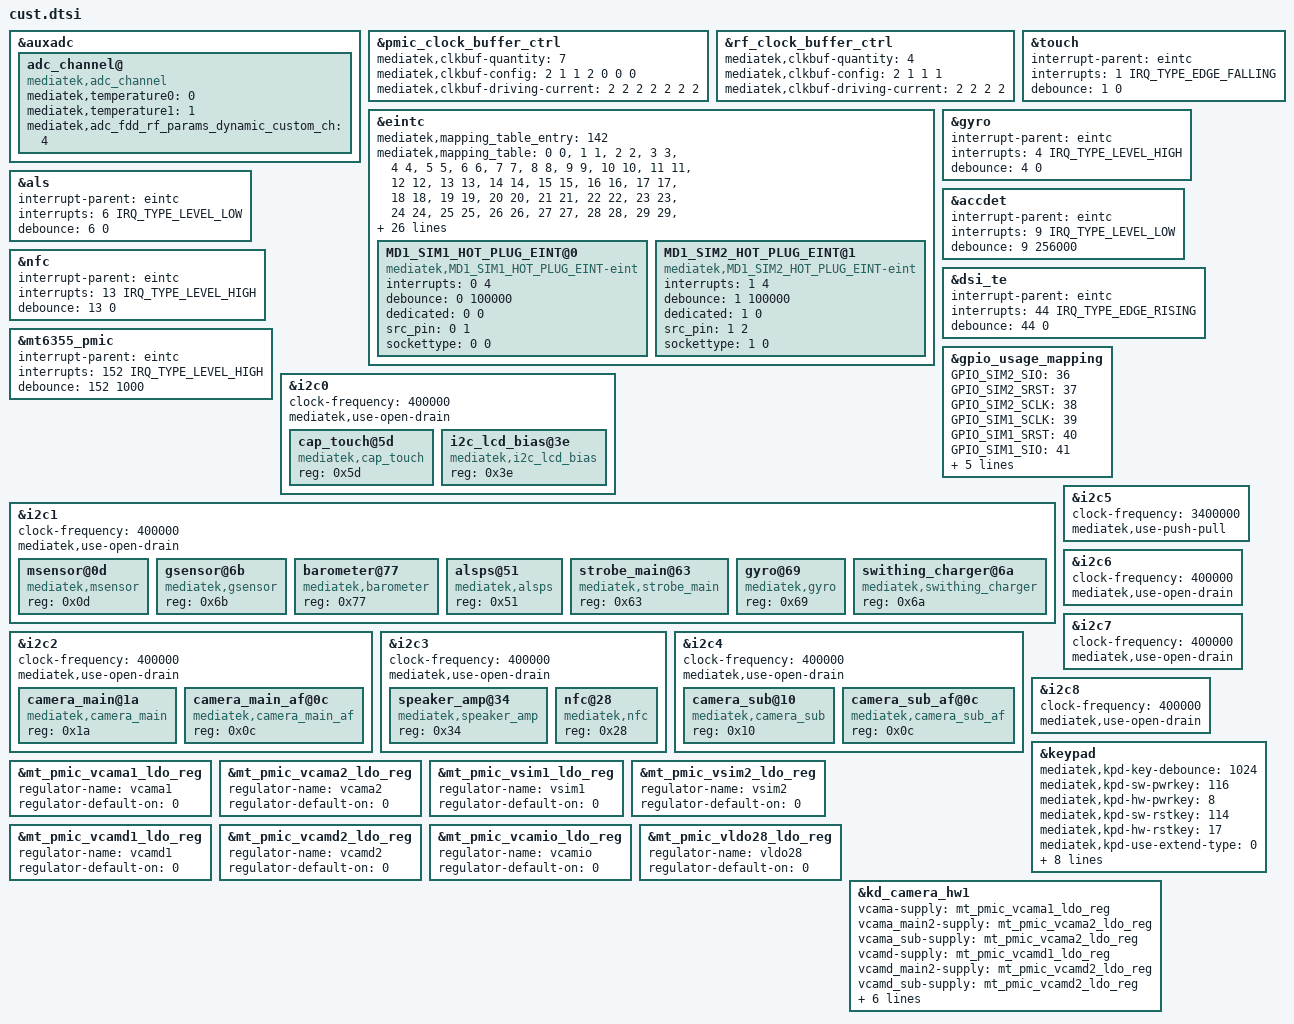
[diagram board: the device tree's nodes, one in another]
/*
 * Generated by MTK SP DrvGen Version: 3.5.160809 for MT6757-P25.
 * 2016-12-20 20:41:03
 * Do Not Modify The File.
 * Copyright Mediatek Inc. (c) 2016.
*/

/*************************
 * ADC DTSI File
*************************/

&auxadc {
	adc_channel@ {
		compatible = "mediatek,adc_channel";
		mediatek,temperature0 = <0>;
		mediatek,temperature1 = <1>;
		mediatek,adc_fdd_rf_params_dynamic_custom_ch = <4>;
		status = "okay";
	};
};


/*************************
 * CLK_BUF DTSI File
*************************/

&pmic_clock_buffer_ctrl {
	mediatek,clkbuf-quantity = <7>;
	mediatek,clkbuf-config = <2 1 1 2 0 0 0>;
	mediatek,clkbuf-driving-current = <2 2 2 2 2 2 2>;
	status = "okay";
};

&rf_clock_buffer_ctrl {
	mediatek,clkbuf-quantity = <4>;
	mediatek,clkbuf-config = <2 1 1 1>;
	mediatek,clkbuf-driving-current = <2 2 2 2 >;
	status = "okay";
};


/*************************
 * EINT DTSI File
*************************/

#include <dt-bindings/interrupt-controller/irq.h>
#include <dt-bindings/interrupt-controller/arm-gic.h>

&eintc {
	mediatek,mapping_table_entry = <142>;
			/* <gpio_pin, eint_pin> */
	mediatek,mapping_table = <0 0>,
					<1 1>,
					<2 2>,
					<3 3>,
					<4 4>,
					<5 5>,
					<6 6>,
					<7 7>,
					<8 8>,
					<9 9>,
					<10 10>,
					<11 11>,
					<12 12>,
					<13 13>,
					<14 14>,
					<15 15>,
					<16 16>,
					<17 17>,
					<18 18>,
					<19 19>,
					<20 20>,
					<21 21>,
					<22 22>,
					<23 23>,
					<24 24>,
					<25 25>,
					<26 26>,
					<27 27>,
					<28 28>,
					<29 29>,
					<30 30>,
					<31 31>,
					<32 32>,
					<33 33>,
					<34 34>,
					<35 35>,
					<36 36>,
					<37 37>,
					<38 38>,
					<39 39>,
					<40 40>,
					<41 41>,
					<42 42>,
					<43 43>,
					<44 44>,
					<45 45>,
					<46 46>,
					<47 47>,
					<48 48>,
					<49 49>,
					<50 50>,
					<51 51>,
					<52 52>,
					<53 53>,
					<54 54>,
					<55 55>,
					<56 56>,
					<57 57>,
					<58 58>,
					<59 59>,
					<60 60>,
					<61 61>,
					<62 62>,
					<63 63>,
					<64 64>,
					<65 65>,
					<66 66>,
					<67 67>,
					<68 68>,
					<69 69>,
					<75 75>,
					<76 76>,
					<77 77>,
					<78 78>,
					<79 79>,
					<80 80>,
					<81 81>,
					<82 82>,
					<83 83>,
					<84 84>,
					<85 85>,
					<86 86>,
					<87 87>,
					<88 88>,
					<89 89>,
					<90 90>,
					<91 91>,
					<92 92>,
					<93 93>,
					<94 94>,
					<95 95>,
					<96 96>,
					<97 97>,
					<98 98>,
					<99 99>,
					<100 100>,
					<101 101>,
					<102 102>,
					<103 103>,
					<104 104>,
					<105 105>,
					<106 106>,
					<107 107>,
					<108 108>,
					<109 109>,
					<110 110>,
					<111 111>,
					<112 112>,
					<113 113>,
					<114 114>,
					<115 115>,
					<116 116>,
					<117 117>,
					<118 118>,
					<119 119>,
					<120 120>,
					<121 121>,
					<122 122>,
					<131 131>,
					<132 132>,
					<133 133>,
					<134 134>,
					<135 135>,
					<136 136>,
					<208 146>,
					<209 147>,
					<195 153>,
					<194 152>,
					<197 155>,
					<196 154>,
					<199 157>,
					<198 156>,
					<201 159>,
					<200 158>,
					<204 141>,
					<210 148>,
					<211 149>,
					<207 145>,
					<205 142>,
					<202 139>,
					<203 140>,
					<206 143>;
	mediatek,builtin_entry = <12>;
					/* gpio, built-in func mode, built-in eint */
	mediatek,builtin_mapping = <152 1 150>, /* 1:PWRAP_SPI0_MI */
					<154 2 150>, /* 2:PWRAP_SPI0_MI */
					<11 2 144>, /* 2:IDDIG */
					<23 2 144>, /* 2:IDDIG */
					<45 6 144>, /* 6:IDDIG */
					<42 1 144>, /* 1:IDDIG */
					<0 4 144>, /* 4:IDDIG */
					<116 4 144>, /* 4:IDDIG */
					<6 3 144>, /* 3:IDDIG */
					<78 2 144>, /* 2:IDDIG */
					<152 2 152>, /* 2:PWRAP_SPI0_MO */
					<154 1 152>;};

&touch {
	interrupt-parent = <&eintc>;
	interrupts = <1 IRQ_TYPE_EDGE_FALLING>;
	debounce = <1 0>;
	status = "okay";
};

&gyro {
	interrupt-parent = <&eintc>;
	interrupts = <4 IRQ_TYPE_LEVEL_HIGH>;
	debounce = <4 0>;
	status = "okay";
};

&als {
	interrupt-parent = <&eintc>;
	interrupts = <6 IRQ_TYPE_LEVEL_LOW>;
	debounce = <6 0>;
	status = "okay";
};

&accdet {
	interrupt-parent = <&eintc>;
	interrupts = <9 IRQ_TYPE_LEVEL_LOW>;
	debounce = <9 256000>;
	status = "okay";
};

&nfc {
	interrupt-parent = <&eintc>;
	interrupts = <13 IRQ_TYPE_LEVEL_HIGH>;
	debounce = <13 0>;
	status = "okay";
};

&dsi_te {
	interrupt-parent = <&eintc>;
	interrupts = <44 IRQ_TYPE_EDGE_RISING>;
	debounce = <44 0>;
	status = "okay";
};

&mt6355_pmic {
	interrupt-parent = <&eintc>;
	interrupts = <152 IRQ_TYPE_LEVEL_HIGH>;
	debounce = <152 1000>;
	status = "okay";
};



/*************************
 * GPIO DTSI File
*************************/

&gpio_usage_mapping {
	GPIO_SIM2_SIO = <36>;
	GPIO_SIM2_SRST = <37>;
	GPIO_SIM2_SCLK = <38>;
	GPIO_SIM1_SCLK = <39>;
	GPIO_SIM1_SRST = <40>;
	GPIO_SIM1_SIO = <41>;
	GPIO_SIM2_HOT_PLUG = <45>;
	GPIO_SIM1_HOT_PLUG = <46>;
	GPIO_FDD_BAND_SUPPORT_DETECT_2ND_PIN = <83>;
	GPIO_FDD_BAND_SUPPORT_DETECT_1ST_PIN = <84>;
	GPIO_FDD_BAND_SUPPORT_DETECT_3RD_PIN = <90>;
};


/*************************
 * I2C DTSI File
*************************/

&i2c0 {
	#address-cells = <1>;
	#size-cells = <0>;
	clock-frequency = <400000>;
	mediatek,use-open-drain;
	cap_touch@5d {
		compatible = "mediatek,cap_touch";
		reg = <0x5d>;
		status = "okay";
	};

	i2c_lcd_bias@3e {
		compatible = "mediatek,i2c_lcd_bias";
		reg = <0x3e>;
		status = "okay";
	};

};

&i2c1 {
	#address-cells = <1>;
	#size-cells = <0>;
	clock-frequency = <400000>;
	mediatek,use-open-drain;
	msensor@0d {
		compatible = "mediatek,msensor";
		reg = <0x0d>;
		status = "okay";
	};

	gsensor@6b {
		compatible = "mediatek,gsensor";
		reg = <0x6b>;
		status = "okay";
	};

	barometer@77 {
		compatible = "mediatek,barometer";
		reg = <0x77>;
		status = "okay";
	};

	alsps@51 {
		compatible = "mediatek,alsps";
		reg = <0x51>;
		status = "okay";
	};

	strobe_main@63 {
		compatible = "mediatek,strobe_main";
		reg = <0x63>;
		status = "okay";
	};

	gyro@69 {
		compatible = "mediatek,gyro";
		reg = <0x69>;
		status = "okay";
	};

	swithing_charger@6a {
		compatible = "mediatek,swithing_charger";
		reg = <0x6a>;
		status = "okay";
	};

};

&i2c2 {
	#address-cells = <1>;
	#size-cells = <0>;
	clock-frequency = <400000>;
	mediatek,use-open-drain;
	camera_main@1a {
		compatible = "mediatek,camera_main";
		reg = <0x1a>;
		status = "okay";
	};

	camera_main_af@0c {
		compatible = "mediatek,camera_main_af";
		reg = <0x0c>;
		status = "okay";
	};

};

&i2c3 {
	#address-cells = <1>;
	#size-cells = <0>;
	clock-frequency = <400000>;
	mediatek,use-open-drain;
	speaker_amp@34 {
		compatible = "mediatek,speaker_amp";
		reg = <0x34>;
		status = "okay";
	};

	nfc@28 {
		compatible = "mediatek,nfc";
		reg = <0x28>;
		status = "okay";
	};

};

&i2c4 {
	#address-cells = <1>;
	#size-cells = <0>;
	clock-frequency = <400000>;
	mediatek,use-open-drain;
	camera_sub@10 {
		compatible = "mediatek,camera_sub";
		reg = <0x10>;
		status = "okay";
	};

	camera_sub_af@0c {
		compatible = "mediatek,camera_sub_af";
		reg = <0x0c>;
		status = "okay";
	};

};

&i2c5 {
	#address-cells = <1>;
	#size-cells = <0>;
	clock-frequency = <3400000>;
	mediatek,use-push-pull;
};

&i2c6 {
	#address-cells = <1>;
	#size-cells = <0>;
	clock-frequency = <400000>;
	mediatek,use-open-drain;
};

&i2c7 {
	#address-cells = <1>;
	#size-cells = <0>;
	clock-frequency = <400000>;
	mediatek,use-open-drain;
};

&i2c8 {
	#address-cells = <1>;
	#size-cells = <0>;
	clock-frequency = <400000>;
	mediatek,use-open-drain;
};



/*************************
 * KPD DTSI File
*************************/

&keypad {
	mediatek,kpd-key-debounce = <1024>;
	mediatek,kpd-sw-pwrkey = <116>;
	mediatek,kpd-hw-pwrkey = <8>;
	mediatek,kpd-sw-rstkey  = <114>;
	mediatek,kpd-hw-rstkey = <17>;
	mediatek,kpd-use-extend-type = <0>;
	/*HW Keycode [0~71] -> Linux Keycode*/
	mediatek,kpd-hw-map-num = <72>;
	mediatek,kpd-hw-init-map = <0 115 102 0 0 0 0 0 0 0 0 0 0 0 0 0 0 0 0 0 0 0 0 0 0 0 0 0 0 0 0 0 0 0 0 0 0 0 0 0 0 0 0 0 0 0 0 0 0 0 0 0 0 0 0 0 0 0 0 0 0 0 0 0 0 0 0 0 0 0 0 0 >;
	mediatek,kpd-pwrkey-eint-gpio = <0>;
	mediatek,kpd-pwkey-gpio-din  = <0>;
	mediatek,kpd-hw-dl-key1 = <17>;
	mediatek,kpd-hw-dl-key2 = <8>;
	mediatek,kpd-hw-factory-key = <17>;
	status = "okay";
};


/*************************
 * MD1_EINT DTSI File
*************************/

&eintc {
	MD1_SIM1_HOT_PLUG_EINT@0 {
		compatible = "mediatek,MD1_SIM1_HOT_PLUG_EINT-eint";
		interrupts = <0 4>;
		debounce = <0 100000>;
		dedicated = <0 0>;
		src_pin = <0 1>;
		sockettype = <0 0>;
		status = "okay";
	};

	MD1_SIM2_HOT_PLUG_EINT@1 {
		compatible = "mediatek,MD1_SIM2_HOT_PLUG_EINT-eint";
		interrupts = <1 4>;
		debounce = <1 100000>;
		dedicated = <1 0>;
		src_pin = <1 2>;
		sockettype = <1 0>;
		status = "okay";
	};

};


/*************************
 * PMIC DTSI File
*************************/

&mt_pmic_vcama1_ldo_reg {
	regulator-name = "vcama1";
	regulator-default-on = <0>; /* 0:skip, 1: off, 2:on */
	status = "okay";
};
&mt_pmic_vcama2_ldo_reg {
	regulator-name = "vcama2";
	regulator-default-on = <0>; /* 0:skip, 1: off, 2:on */
	status = "okay";
};
&mt_pmic_vsim1_ldo_reg {
	regulator-name = "vsim1";
	regulator-default-on = <0>; /* 0:skip, 1: off, 2:on */
	status = "okay";
};
&mt_pmic_vsim2_ldo_reg {
	regulator-name = "vsim2";
	regulator-default-on = <0>; /* 0:skip, 1: off, 2:on */
	status = "okay";
};
&mt_pmic_vcamd1_ldo_reg {
	regulator-name = "vcamd1";
	regulator-default-on = <0>; /* 0:skip, 1: off, 2:on */
	status = "okay";
};
&mt_pmic_vcamd2_ldo_reg {
	regulator-name = "vcamd2";
	regulator-default-on = <0>; /* 0:skip, 1: off, 2:on */
	status = "okay";
};
&mt_pmic_vcamio_ldo_reg {
	regulator-name = "vcamio";
	regulator-default-on = <0>; /* 0:skip, 1: off, 2:on */
	status = "okay";
};
&mt_pmic_vldo28_ldo_reg {
	regulator-name = "vldo28";
	regulator-default-on = <0>; /* 0:skip, 1: off, 2:on */
	status = "okay";
};

&kd_camera_hw1 {
	vcama-supply = <&mt_pmic_vcama1_ldo_reg>;
	vcama_main2-supply = <&mt_pmic_vcama2_ldo_reg>;
	vcama_sub-supply = <&mt_pmic_vcama2_ldo_reg>;
	vcamd-supply = <&mt_pmic_vcamd1_ldo_reg>;
	vcamd_main2-supply = <&mt_pmic_vcamd2_ldo_reg>;
	vcamd_sub-supply = <&mt_pmic_vcamd2_ldo_reg>;
	vcamio-supply = <&mt_pmic_vcamio_ldo_reg>;
	vcamio_main2-supply = <&mt_pmic_vcamio_ldo_reg>;
	vcamio_sub-supply = <&mt_pmic_vcamio_ldo_reg>;
	vcamaf-supply = <&mt_pmic_vldo28_ldo_reg>;
	vcamaf_main2-supply = <&mt_pmic_vldo28_ldo_reg>;
	vcamaf_sub-supply = <&mt_pmic_vldo28_ldo_reg>;
	status = "okay";
};

&touch {
	status = "okay";
};


/*************************
 * POWER DTSI File
*************************/



